AUTOSAR XML (schema 4-2-2)
package /ComponentTypes
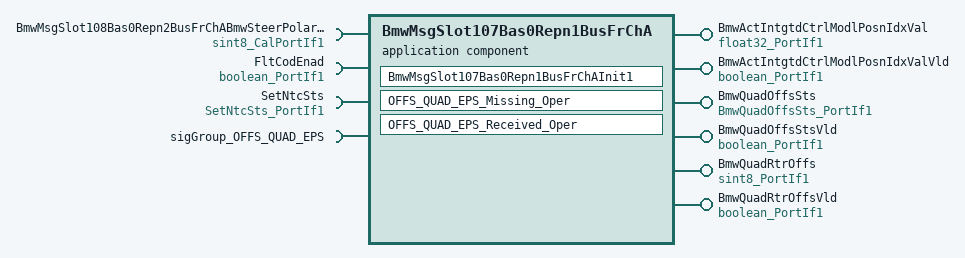
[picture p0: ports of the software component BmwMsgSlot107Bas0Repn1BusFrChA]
  application sw component type BmwMsgSlot107Bas0Repn1BusFrChA
    6 x provide port:
      BmwActIntgtdCtrlModlPosnIdxVal: nonqueued-sender-com-spec=data-element=Val, provided-interface=float32_PortIf1
      BmwActIntgtdCtrlModlPosnIdxValVld: nonqueued-sender-com-spec{data-element=Logl, init-value=0}, provided-interface=boolean_PortIf1
      BmwQuadOffsSts: nonqueued-sender-com-spec{data-element=Val, init-value=15}, provided-interface=BmwQuadOffsSts_PortIf1
      BmwQuadOffsStsVld: nonqueued-sender-com-spec{data-element=Logl, init-value=0}, provided-interface=boolean_PortIf1
      BmwQuadRtrOffs: nonqueued-sender-com-spec{data-element=Val, init-value=0}, provided-interface=sint8_PortIf1
      BmwQuadRtrOffsVld: nonqueued-sender-com-spec{data-element=Logl, init-value=0}, provided-interface=boolean_PortIf1
    4 x require port:
      BmwMsgSlot108Bas0Repn2BusFrChABmwSteerPolarity: parameter-require-com-spec{init-value=-1, parameter=Val}, required-interface=sint8_CalPortIf1
      FltCodEnad: nonqueued-receiver-com-spec{data-element=Logl, filter=data-filter-type=ALWAYS, init-value=1}, required-interface=boolean_PortIf1
      SetNtcSts: client-com-spec=Oper, required-interface=SetNtcSts_PortIf1
      sigGroup_OFFS_QUAD_EPS: nonqueued-receiver-com-spec{data-element=sigGroup_OFFS_QUAD_EPS, uses-end-to-end-protection=true, alive-timeout=1.1, enable-update=true, filter=data-filter-type=ALWAYS, init-value=fields=[AVL_PO_IDX_ICM:65535, ST_OFFS_QUAD_EPS:15, CRC_OFFS_QUAD_EPS:0, OFFS_QUAD_RTR_EPS:255, ALIV_OFFS_QUAD_EPS:0]}, required-interface=sigGroup_OFFS_QUAD_EPS
    behavior BmwMsgSlot107Bas0Repn1BusFrChA_InternalBehavior
      ar-typed-per-instance-memorys:
        18 x data, all with sw-calibration-access=READ-ONLY:
          AlvFaildCnt: type=uint8
          AlvPassdCnt: type=uint8
          AvlPoIdxIcmFaildCnt: type=uint8
          AvlPoIdxIcmPassdCnt: type=uint8
          BmwActIntgtdCtrlModlPosnIdxValPrev: type=float32
          BmwQuadOffsStsPrev: type=BmwQuadOffsSts1
          BmwQuadRtrOffsPrev: type=sint8
          CrcFaildCnt: type=uint8
          CrcPassdCnt: type=uint8
          Dummy_PIM1: type=AVL_PO_IDX_ICM1
          Dummy_PIM2: type=ST_OFFS_QUAD_EPS1
          Dummy_PIM3: type=OFFS_QUAD_RTR_EPS1
          MissMsgCnt: type=uint8
          OffsQuadRtrEpsFaildCnt: type=uint8
          OffsQuadRtrEpsPassdCnt: type=uint8
          RxdMsgCnt: type=uint8
          StOffsQuadEpsFaildCnt: type=uint8
          StOffsQuadEpsPassdCnt: type=uint8
      init event BmwMsgSlot107Bas0Repn1BusFrChAInit1_InitEvent: start-on-event=BmwMsgSlot107Bas0Repn1BusFrChAInit1
      data receive error event DRET_OFFS_QUAD_EPS_Missing_Oper_sigGroup_OFFS_QUAD_EPS_sigGroup_OFFS_QUAD_EPS: start-on-event=OFFS_QUAD_EPS_Missing_Oper, data=sigGroup_OFFS_QUAD_EPS.sigGroup_OFFS_QUAD_EPS
      data received event DRT_OFFS_QUAD_EPS_Received_Oper_sigGroup_OFFS_QUAD_EPS_sigGroup_OFFS_QUAD_EPS: start-on-event=OFFS_QUAD_EPS_Received_Oper, data=sigGroup_OFFS_QUAD_EPS.sigGroup_OFFS_QUAD_EPS
      port-api-options:
        enable-take-address=false, error-handling=NO-TRANSFORMER-ERROR-HANDLING, indirect-api=false, port=BmwActIntgtdCtrlModlPosnIdxVal
        enable-take-address=false, error-handling=NO-TRANSFORMER-ERROR-HANDLING, indirect-api=false, port=BmwActIntgtdCtrlModlPosnIdxValVld
        enable-take-address=false, error-handling=NO-TRANSFORMER-ERROR-HANDLING, indirect-api=false, port=BmwMsgSlot108Bas0Repn2BusFrChABmwSteerPolarity
        enable-take-address=false, error-handling=NO-TRANSFORMER-ERROR-HANDLING, indirect-api=false, port=BmwQuadOffsSts
        enable-take-address=false, error-handling=NO-TRANSFORMER-ERROR-HANDLING, indirect-api=false, port=BmwQuadOffsStsVld
        enable-take-address=false, error-handling=NO-TRANSFORMER-ERROR-HANDLING, indirect-api=false, port=BmwQuadRtrOffs
        enable-take-address=false, error-handling=NO-TRANSFORMER-ERROR-HANDLING, indirect-api=false, port=BmwQuadRtrOffsVld
        enable-take-address=false, error-handling=NO-TRANSFORMER-ERROR-HANDLING, indirect-api=false, port=FltCodEnad
        enable-take-address=false, error-handling=NO-TRANSFORMER-ERROR-HANDLING, indirect-api=false, port=SetNtcSts
        enable-take-address=false, error-handling=NO-TRANSFORMER-ERROR-HANDLING, indirect-api=false, port=sigGroup_OFFS_QUAD_EPS
      runnable BmwMsgSlot107Bas0Repn1BusFrChAInit1
        data-receive-point-by-arguments:
          access REC_FltCodEnad_Logl: accessed-variable=FltCodEnad.Logl
          access REC_sigGroup_OFFS_QUAD_EPS_sigGroup_OFFS_QUAD_EPS: accessed-variable=sigGroup_OFFS_QUAD_EPS.sigGroup_OFFS_QUAD_EPS
        data-send-points:
          4 x access:
            SEND_BmwActIntgtdCtrlModlPosnIdxValVld_Logl: accessed-variable=BmwActIntgtdCtrlModlPosnIdxValVld.Logl
            SEND_BmwQuadOffsSts_Val: accessed-variable=BmwQuadOffsSts.Val
            SEND_BmwQuadOffsStsVld_Logl: accessed-variable=BmwQuadOffsStsVld.Logl
            SEND_BmwQuadRtrOffsVld_Logl: accessed-variable=BmwQuadRtrOffsVld.Logl
        sync call SC_SetNtcSts_Oper: operation=SetNtcSts.Oper, timeout=0
      runnable OFFS_QUAD_EPS_Missing_Oper
        data-receive-point-by-arguments:
          access REC_FltCodEnad_Logl: accessed-variable=FltCodEnad.Logl
          access REC_sigGroup_OFFS_QUAD_EPS_sigGroup_OFFS_QUAD_EPS: accessed-variable=sigGroup_OFFS_QUAD_EPS.sigGroup_OFFS_QUAD_EPS
        data-send-points:
          6 x access:
            SEND_BmwActIntgtdCtrlModlPosnIdxVal_Val_1: accessed-variable=BmwActIntgtdCtrlModlPosnIdxVal.Val
            SEND_BmwActIntgtdCtrlModlPosnIdxValVld_Logl: accessed-variable=BmwActIntgtdCtrlModlPosnIdxValVld.Logl
            SEND_BmwQuadOffsSts_Val: accessed-variable=BmwQuadOffsSts.Val
            SEND_BmwQuadOffsStsVld_Logl: accessed-variable=BmwQuadOffsStsVld.Logl
            SEND_BmwQuadRtrOffs_Val_1: accessed-variable=BmwQuadRtrOffs.Val
            SEND_BmwQuadRtrOffsVld_Logl: accessed-variable=BmwQuadRtrOffsVld.Logl
        sync call SC_SetNtcSts_Oper: operation=SetNtcSts.Oper, timeout=0
      runnable OFFS_QUAD_EPS_Received_Oper
        data-receive-point-by-arguments:
          access REC_FltCodEnad_Logl: accessed-variable=FltCodEnad.Logl
          access REC_sigGroup_OFFS_QUAD_EPS_sigGroup_OFFS_QUAD_EPS: accessed-variable=sigGroup_OFFS_QUAD_EPS.sigGroup_OFFS_QUAD_EPS
        data-send-points:
          6 x access:
            SEND_BmwActIntgtdCtrlModlPosnIdxVal_Val_1: accessed-variable=BmwActIntgtdCtrlModlPosnIdxVal.Val
            SEND_BmwActIntgtdCtrlModlPosnIdxValVld_Logl: accessed-variable=BmwActIntgtdCtrlModlPosnIdxValVld.Logl
            SEND_BmwQuadOffsSts_Val: accessed-variable=BmwQuadOffsSts.Val
            SEND_BmwQuadOffsStsVld_Logl: accessed-variable=BmwQuadOffsStsVld.Logl
            SEND_BmwQuadRtrOffs_Val_1: accessed-variable=BmwQuadRtrOffs.Val
            SEND_BmwQuadRtrOffsVld_Logl: accessed-variable=BmwQuadRtrOffsVld.Logl
        sync call SC_SetNtcSts_Oper: operation=SetNtcSts.Oper, timeout=0
  swc implementation BmwMsgSlot107Bas0Repn1BusFrChA_Implementation: behavior=BmwMsgSlot107Bas0Repn1BusFrChA_InternalBehavior
    code-descriptors:
      code Default: artifact-descriptors=autosar-engineering-object={short-label=Default, category=SWSRC}
